# MSP430FR6972 register map
Registers are 16-bit, read-write, reset 0x0 unless marked. A register's access mark holds for its fields unless they carry their own. Offsets are from the block's base; [hi:lo] are bit positions; {n}, {i} and the like mark numbered series.

## CAPACITIVE_TOUCH_IO_1
Base 0x0000047E
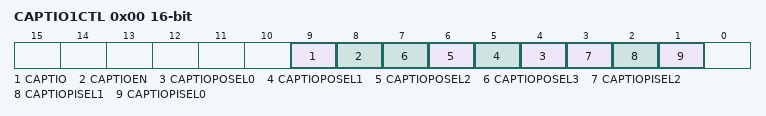
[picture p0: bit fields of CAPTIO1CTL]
0x00 CAPTIO1CTL — Capacitive_Touch_IO 1 control register
  [9] CAPTIO — CapTouchIO state
  [8] CAPTIOEN — CapTouchIO Enable
  [n+4] CAPTIOPOSEL{n} (n=0..3) — CapTouchIO Port Select Bit: {n}
  [3] CAPTIOPISEL2 — CapTouchIO Pin Select Bit: 2
  [2] CAPTIOPISEL1 — CapTouchIO Pin Select Bit: 1
  [1] CAPTIOPISEL0 — CapTouchIO Pin Select Bit: 0

## MPY_16 — MPY 16 Multiplier 16 Bit Mode
Base 0x000004C0
0x00 MPY — Multiply Unsigned/Operand 1
0x02 MPYS — Multiply Signed/Operand 1
0x04 MAC — Multiply Unsigned and Accumulate/Operand 1
0x06 MACS — Multiply Signed and Accumulate/Operand 1
0x08 OP2 — Operand 2
0x0A RESLO — Result Low Word
0x0C RESHI — Result High Word
0x0E SUMEXT — Sum Extend
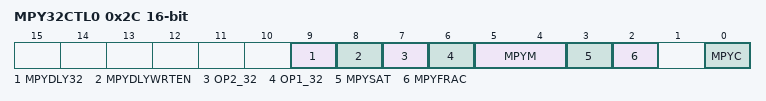
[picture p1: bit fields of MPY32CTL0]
0x2C MPY32CTL0 — MPY32 Control Register 0
  [9] MPYDLY32 — Delayed write mode
  [8] MPYDLYWRTEN — Delayed write enable
  [7] OP2_32 — Bit-width of operand 2 0:16Bit / 1:32Bit
  [6] OP1_32 — Bit-width of operand 1 0:16Bit / 1:32Bit
  [5:4] MPYM — Multiplier mode Bit:0
    0=Multiplier mode: MPY; 1=Multiplier mode: MPYS; 2=Multiplier mode: MAC; 3=Multiplier mode: MACS
  [3] MPYSAT — Saturation mode
  [2] MPYFRAC — Fractional mode
  [0] MPYC — Carry of the multiplier

## MPY_32 — MPY 32 Multiplier 32 Bit Mode
Base 0x000004D0
0x00 MPY32L — 32-bit operand 1 - multiply - low word
0x02 MPY32H — 32-bit operand 1 - multiply - high word
0x04 MPYS32L — 32-bit operand 1 - signed multiply - low word
0x06 MPYS32H — 32-bit operand 1 - signed multiply - high word
0x08 MAC32L — 32-bit operand 1 - multiply accumulate - low word
0x0A MAC32H — 32-bit operand 1 - multiply accumulate - high word
0x0C MACS32L — 32-bit operand 1 - signed multiply accumulate - low word
0x0E MACS32H — 32-bit operand 1 - signed multiply accumulate - high word
0x10 OP2L — 32-bit operand 2 - low word
0x12 OP2H — 32-bit operand 2 - high word
0x14 RES0 — 32x32-bit result 0 - least significant word
0x16 RES1 — 32x32-bit result 1
0x18 RES2 — 32x32-bit result 2
0x1A RES3 — 32x32-bit result 3 - most significant word

## DMA
Base 0x00000500
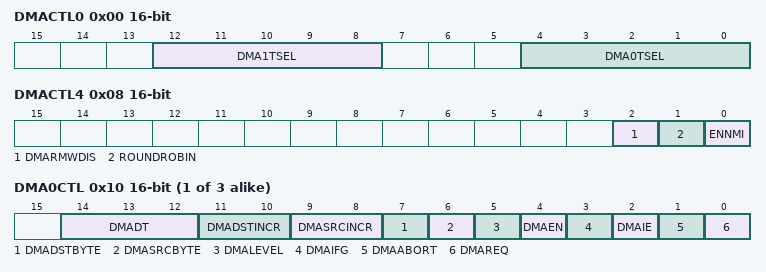
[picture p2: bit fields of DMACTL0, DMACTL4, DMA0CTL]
0x00 DMACTL0 — DMA Module Control 0
  [12:8] DMA1TSEL — DMA channel 1 transfer select bit 0
    0=DMA channel 1 transfer select 0: DMA_REQ (sw); {v}=DMA channel 1 transfer select {v}: (v=1..29); 30=DMA channel 1 transfer select 30: previous DMA channel DMA0IFG; 31=DMA channel 1 transfer select 31: ext. Trigger (DMAE0)
  [4:0] DMA0TSEL — DMA channel 0 transfer select bit 0
    0=DMA channel 0 transfer select 0: DMA_REQ (sw); {v}=DMA channel 0 transfer select {v}: (v=1..29); 30=DMA channel 0 transfer select 30: previous DMA channel DMA2IFG; 31=DMA channel 0 transfer select 31: ext. Trigger (DMAE0)
0x02 DMACTL1 — DMA Module Control 1
  [4:0] DMA2TSEL — DMA channel 2 transfer select bit 0
    0=DMA channel 2 transfer select 0: DMA_REQ (sw); {v}=DMA channel 2 transfer select {v}: (v=1..29); 30=DMA channel 2 transfer select 30: previous DMA channel DMA1IFG; 31=DMA channel 2 transfer select 31: ext. Trigger (DMAE0)
0x04 DMACTL2 — DMA Module Control 2
0x06 DMACTL3 — DMA Module Control 3
0x08 DMACTL4 — DMA Module Control 4
  [2] DMARMWDIS — Inhibited DMA transfers during read-modify-write CPU operations
  [1] ROUNDROBIN — Round-Robin DMA channel priorities
  [0] ENNMI — Enable NMI interruption of DMA
0x0E DMAIV — DMA Interrupt Vector Word
{0x10+0x10*i} DMA{i}CTL (i=0..2) — DMA Channel {i} Control
  [14:12] DMADT — DMA transfer mode bit 0
    0=DMA transfer mode 0: Single transfer; 1=DMA transfer mode 1: Block transfer; 2=DMA transfer mode 2: Burst-Block transfer; 3=DMA transfer mode 3: Burst-Block transfer; 4=DMA transfer mode 4: Repeated Single transfer; 5=DMA transfer mode 5: Repeated Block transfer; 6=DMA transfer mode 6: Repeated Burst-Block transfer; 7=DMA transfer mode 7: Repeated Burst-Block transfer
  [11:10] DMADSTINCR — DMA destination increment bit 0
    0=DMA destination increment 0: destination address unchanged; 1=DMA destination increment 1: destination address unchanged; 2=DMA destination increment 2: destination address decremented; 3=DMA destination increment 3: destination address incremented
  [9:8] DMASRCINCR — DMA source increment bit 0
    0=DMA source increment 0: source address unchanged; 1=DMA source increment 1: source address unchanged; 2=DMA source increment 2: source address decremented; 3=DMA source increment 3: source address incremented
  [7] DMADSTBYTE — DMA destination byte
  [6] DMASRCBYTE — DMA source byte
  [5] DMALEVEL — DMA level sensitive trigger select
  [4] DMAEN — DMA enable
  [3] DMAIFG — DMA interrupt flag
  [2] DMAIE — DMA interrupt enable
  [1] DMAABORT — DMA transfer aborted by NMI
  [0] DMAREQ — Initiate DMA transfer with DMATSEL
{0x12+0x10*i} DMA{i}SA 32-bit (i=0..2) — DMA Channel {i} Source Address
{0x16+0x10*i} DMA{i}DA 32-bit (i=0..2) — DMA Channel {i} Destination Address
{0x1A+0x10*i} DMA{i}SZ (i=0..2) — DMA Channel {i} Transfer Size
